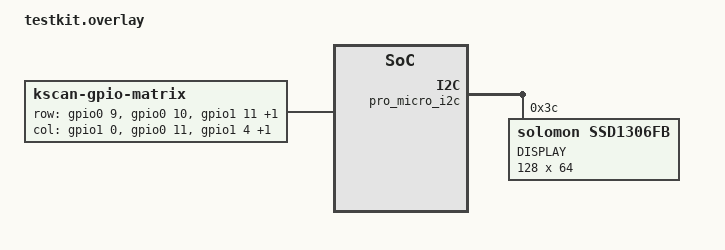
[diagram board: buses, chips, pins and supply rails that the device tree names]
#include <dt-bindings/zmk/matrix_transform.h>

/ {
    chosen {
        zephyr,display = &oled;
        zmk,kscan = &kscan0;
    };

    kscan0: kscan_0 {
        compatible = "zmk,kscan-gpio-matrix";
        label = "KSCAN";
        diode-direction = "col2row";

         row-gpios
            = <&gpio0 9 (GPIO_ACTIVE_HIGH | GPIO_PULL_DOWN)>
            , <&gpio0 10 (GPIO_ACTIVE_HIGH | GPIO_PULL_DOWN)>
            , <&gpio1 11 (GPIO_ACTIVE_HIGH | GPIO_PULL_DOWN)>
            , <&gpio1 13 (GPIO_ACTIVE_HIGH | GPIO_PULL_DOWN)>
            ;

        col-gpios
            = <&gpio1 0 GPIO_ACTIVE_HIGH>
            , <&gpio0 11 GPIO_ACTIVE_HIGH>
            , <&gpio1 4 GPIO_ACTIVE_HIGH>
            , <&gpio1 6 GPIO_ACTIVE_HIGH>
            ;
    };

    encoder_1: encoder_1 {
        compatible = "alps,ec11";
        label = "Encoder 1";
        a-gpios = <&gpio1 15 (GPIO_ACTIVE_LOW | GPIO_PULL_UP)>;
        b-gpios = <&gpio0 2 (GPIO_ACTIVE_LOW | GPIO_PULL_UP)>;
        resolution = <4>;
        status = "disabled";
    };
};

&pro_micro_i2c {
    status = "okay";

    oled: ssd1306@3c {
        compatible = "solomon,ssd1306fb";
        reg = <0x3c>;
        label = "DISPLAY";
        width = <128>;
        height = <64>;
        segment-offset = <0>;
        page-offset = <0>;
        display-offset = <0>;
        multiplex-ratio = <31>;
        segment-remap;
        com-invdir;
        com-sequential;
        prechargep = <0x22>;
    };
};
